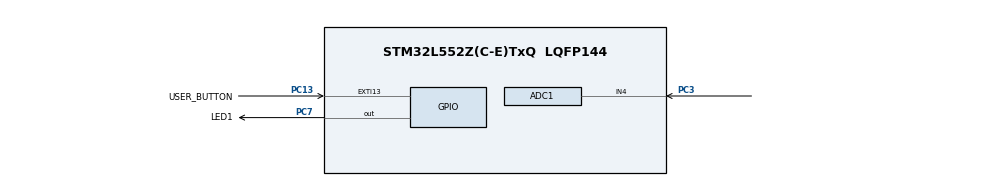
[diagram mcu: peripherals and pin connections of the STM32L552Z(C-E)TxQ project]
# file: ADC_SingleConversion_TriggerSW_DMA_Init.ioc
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ADC1.Channel-12\#ChannelRegularConversion=ADC_CHANNEL_4
ADC1.ClockPrescaler=ADC_CLOCK_SYNC_PCLK_DIV2
ADC1.EnableRegularConversion=ENABLE
ADC1.NbrOfConversionFlag=1
ADC1.OffsetNumber-12\#ChannelRegularConversion=ADC_OFFSET_NONE
ADC1.Rank-12\#ChannelRegularConversion=1
ADC1.SamplingTime-12\#ChannelRegularConversion=ADC_SAMPLETIME_47CYCLES_5
ADC1.master=1
Dma.ADC1.0.Channel_PRIV_NPRIV=DMA_CHANNEL_NPRIV_DISABLE
Dma.ADC1.0.Direction=DMA_PERIPH_TO_MEMORY
Dma.ADC1.0.EventEnable=DISABLE
Dma.ADC1.0.Instance=DMA1_Channel1
Dma.ADC1.0.MemDataAlignment=DMA_MDATAALIGN_HALFWORD
Dma.ADC1.0.MemInc=DMA_MINC_ENABLE
Dma.ADC1.0.Mode=DMA_NORMAL
Dma.ADC1.0.PeriphDataAlignment=DMA_PDATAALIGN_HALFWORD
Dma.ADC1.0.PeriphInc=DMA_PINC_DISABLE
Dma.ADC1.0.Polarity=HAL_DMAMUX_REQ_GEN_RISING
Dma.ADC1.0.Priority=DMA_PRIORITY_LOW
Dma.ADC1.0.RequestNumber=1
Dma.ADC1.0.SignalID=NONE
Dma.ADC1.0.SyncEnable=DISABLE
Dma.ADC1.0.SyncPolarity=HAL_DMAMUX_SYNC_NO_EVENT
Dma.ADC1.0.SyncRequestNumber=1
Dma.ADC1.0.SyncSignalID=NONE
Dma.Request0=ADC1
Mcu.Family=STM32L5
Mcu.Name=STM32L552Z(C-E)TxQ
Mcu.Package=LQFP144
NVIC.DMA1_Channel1_IRQn=true\:0\:0\:false\:false\:true\:false\:true\:true
NVIC.PriorityGroup=NVIC_PRIORITYGROUP_3
PC13.GPIO_Label=USER_BUTTON
PC13.Signal=GPXTI13
PC3.Signal=ADCx_IN4
PC7.GPIO_Label=LED1
PC7.Signal=GPIO_Output
ProjectManager.HeapSize=0x200
ProjectManager.StackSize=0x400
ProjectManager.TargetToolchain=EWARM V8.32
RCC.ADCCLockSelection=RCC_ADCCLKSOURCE_SYSCLK
RCC.ADCFreq_Value=110000000
RCC.AHBFreq_Value=110000000
RCC.APB1Freq_Value=110000000
RCC.APB1TimFreq_Value=110000000
RCC.APB2Freq_Value=110000000
RCC.APB2TimFreq_Value=110000000
RCC.CortexFreq_Value=110000000
RCC.HCLKFreq_Value=110000000
RCC.HSE_VALUE=16000000
RCC.HSI48_VALUE=48000000
RCC.HSI_VALUE=16000000
RCC.LSE_VALUE=32768
RCC.MSI_VALUE=4000000
RCC.PLLN=55
RCC.PLLSAI1N=24
RCC.RTCClockSelection=RCC_RTCCLKSOURCE_LSE
RCC.SYSCLKFreq_VALUE=110000000
RCC.SYSCLKSource=RCC_SYSCLKSOURCE_PLLCLK
RCC.USBFreq_Value=48000000
RCC.VCOOutputFreq_Value=220000000
SH.ADCx_IN4.0=ADC1_IN4,IN4-Single-Ended
VP_ICACHE_VS_ICACHE.Mode=DirectMappedCache
VP_PWR_VS_DBSignals.Mode=DisableDeadBatterySignals
board=custom

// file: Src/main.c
/* USER CODE BEGIN Header */
/**
  ******************************************************************************
  * @file    Examples_LL/ADC/ADC_SingleConversion_TriggerSW_DMA_Init/Src/main.c
  * @author  MCD Application Team
  * @brief   This example describes how to use a ADC peripheral to perform
  *          a single ADC conversion of a channel, at each software start.
  *          Example using programming model: DMA transfer
  *          (for programming models polling or interrupt, refer to
  *          other examples).
  *          This example is based on the STM32L5xx ADC LL API;
  *          Peripheral initialization done using LL unitary services functions.
  ******************************************************************************
  * @attention
  *
  * Copyright (c) 2019 STMicroelectronics.
  * All rights reserved.
  *
  * This software is licensed under terms that can be found in the LICENSE file
  * in the root directory of this software component.
  * If no LICENSE file comes with this software, it is provided AS-IS.
  *
  ******************************************************************************
  */
/* USER CODE END Header */
#include "main.h"

/* USER CODE BEGIN PD */

/* Definitions of ADC hardware constraints delays */
/* Note: Only ADC IP HW delays are defined in ADC LL driver driver,           */
/*       not timeout values:                                                  */
/*       Timeout values for ADC operations are dependent to device clock      */
/*       configuration (system clock versus ADC clock),                       */
/*       and therefore must be defined in user application.                   */
/*       Refer to @ref ADC_LL_EC_HW_DELAYS for description of ADC timeout     */
/*       values definition.                                                   */

  /* Timeout values for ADC operations. */
  /* (calibration, enable settling time, disable settling time, ...)          */
  /* Values defined to be higher than worst cases: low clock frequency,       */
  /* maximum prescalers.                                                      */
  #define ADC_CALIBRATION_TIMEOUT_MS       (   1U)
  #define ADC_ENABLE_TIMEOUT_MS            (   1U)
  #define ADC_DISABLE_TIMEOUT_MS           (   1U)
  #define ADC_STOP_CONVERSION_TIMEOUT_MS   (   1U)
  #define ADC_CONVERSION_TIMEOUT_MS        ( 500U)

  /* Delay between ADC end of calibration and ADC enable.                     */
  /* Delay estimation in CPU cycles: Case of ADC enable done                  */
  /* immediately after ADC calibration, ADC clock setting slow                */
  /* (LL_ADC_CLOCK_ASYNC_DIV32). Use a higher delay if ratio                  */
  /* (CPU clock / ADC clock) is above 32.                                     */
  #define ADC_DELAY_CALIB_ENABLE_CPU_CYCLES  (LL_ADC_DELAY_CALIB_ENABLE_ADC_CYCLES * 32)

/* Definitions of environment analog values */
  /* Value of analog reference voltage (Vref+), connected to analog voltage   */
  /* supply Vdda (unit: mV).                                                  */
  #define VDDA_APPLI                       (3300UL)

/* Definitions of data related to this example */
  /* Definition of ADCx conversions data table size */
  #define ADC_CONVERTED_DATA_BUFFER_SIZE   (   4UL)

  /* Init variable out of expected ADC conversion data range */
  #define VAR_CONVERTED_DATA_INIT_VALUE    (__LL_ADC_DIGITAL_SCALE(LL_ADC_RESOLUTION_12B) + 1)

/* USER CODE END PD */

/* USER CODE BEGIN PV */

/* Variables for ADC conversion data */
__IO uint16_t aADCxConvertedData[ADC_CONVERTED_DATA_BUFFER_SIZE]; /* ADC group regular conversion data */

/* Variables for ADC conversion data computation to physical values */
__IO uint16_t aADCxConvertedData_Voltage_mVolt[ADC_CONVERTED_DATA_BUFFER_SIZE];  /* Value of voltage calculated from ADC conversion data (unit: mV) (array of data) */

/* Variable to report status of DMA transfer of ADC group regular conversions */
/*  0: DMA transfer is not completed                                          */
/*  1: DMA transfer is completed                                              */
/*  2: DMA transfer has not yet been started yet (initial state)              */
__IO uint8_t ubDmaTransferStatus = 2U; /* Variable set into DMA interruption callback */

/* USER CODE END PV */

void SystemClock_Config(void);
static void MX_GPIO_Init(void);
static void MX_DMA_Init(void);
static void MX_ICACHE_Init(void);
static void MX_ADC1_Init(void);
/* USER CODE BEGIN PFP */

void     Activate_ADC(void);
void     LED_On(void);
void     LED_Off(void);
void     LED_Blinking(uint32_t Period);
void     UserButton_Init(void);

/* USER CODE END PFP */

int main(void)
{
  /* USER CODE BEGIN 1 */

  uint32_t tmp_index_adc_converted_data = 0UL;

  /* USER CODE END 1 */

  /* MCU Configuration--------------------------------------------------------*/

  /* Reset of all peripherals, Initializes the Flash interface and the Systick. */
  LL_APB2_GRP1_EnableClock(LL_APB2_GRP1_PERIPH_SYSCFG);
  LL_APB1_GRP1_EnableClock(LL_APB1_GRP1_PERIPH_PWR);

  /* System interrupt init*/
  NVIC_SetPriorityGrouping(NVIC_PRIORITYGROUP_3);

  /** Disable the internal Pull-Up in Dead Battery pins of UCPD peripheral
  */
  LL_PWR_DisableUCPDDeadBattery();

  /* Configure the system clock */
  SystemClock_Config();

  /* USER CODE BEGIN SysInit */

  /* Init variable containing ADC conversion data */
  for (tmp_index_adc_converted_data = 0; tmp_index_adc_converted_data < ADC_CONVERTED_DATA_BUFFER_SIZE; tmp_index_adc_converted_data++)
  {
    aADCxConvertedData[tmp_index_adc_converted_data] = VAR_CONVERTED_DATA_INIT_VALUE;
  }

  /* USER CODE END SysInit */

  /* Initialize all configured peripherals */
  MX_GPIO_Init();
  MX_DMA_Init();
  MX_ICACHE_Init();
  MX_ADC1_Init();
  /* USER CODE BEGIN 2 */

  /* Initialize button in EXTI mode */
  UserButton_Init();

  /* Activate ADC */
  /* Perform ADC activation procedure to make it ready to convert. */
  Activate_ADC();

  /* USER CODE END 2 */

  /* Infinite loop */
  /* USER CODE BEGIN WHILE */
  while (1)
  {
    /* Note: ADC group regular conversion start is done into push button      */
    /*       IRQ handler, refer to function "UserButton_Callback()".          */

    /* Note: LED state depending on DMA transfer status is set into DMA       */
    /*       IRQ handler,                                                     */
    /*       refer to functions "AdcDmaTransferComplete_Callback()"           */
    /*       and "AdcDmaTransferHalf_Callback()".                             */

    /* Note: ADC conversions data are stored into array                       */
    /*       "aADCxConvertedData"                                             */
    /*       (for debug: see variable content into watch window).             */

    /* Note: ADC conversion data are computed to physical values              */
    /*       into array "aADCxConvertedData_Voltage_mVolt"                    */
    /*       using ADC LL driver helper macro "__LL_ADC_CALC_DATA_TO_VOLTAGE()". */
    /*       (for debug: see variable content into watch window).             */

    /* USER CODE END WHILE */

  }
}

void SystemClock_Config(void)
{
  LL_FLASH_SetLatency(LL_FLASH_LATENCY_5);
  while(LL_FLASH_GetLatency()!= LL_FLASH_LATENCY_5)
  {
  }

  LL_PWR_SetRegulVoltageScaling(LL_PWR_REGU_VOLTAGE_SCALE0);
  LL_RCC_MSI_Enable();

   /* Wait till MSI is ready */
  while(LL_RCC_MSI_IsReady() != 1)
  {
  }

  LL_RCC_MSI_EnableRangeSelection();
  LL_RCC_MSI_SetRange(LL_RCC_MSIRANGE_6);
  LL_RCC_MSI_SetCalibTrimming(0);
  LL_RCC_PLL_ConfigDomain_SYS(LL_RCC_PLLSOURCE_MSI, LL_RCC_PLLM_DIV_1, 55, LL_RCC_PLLR_DIV_2);
  LL_RCC_PLL_EnableDomain_SYS();
  LL_RCC_PLL_Enable();

   /* Wait till PLL is ready */
  while(LL_RCC_PLL_IsReady() != 1)
  {
  }

   /* Intermediate AHB prescaler 2 when target frequency clock is higher than 80 MHz */
   LL_RCC_SetAHBPrescaler(LL_RCC_SYSCLK_DIV_2);

  LL_RCC_SetSysClkSource(LL_RCC_SYS_CLKSOURCE_PLL);

   /* Wait till System clock is ready */
  while(LL_RCC_GetSysClkSource() != LL_RCC_SYS_CLKSOURCE_STATUS_PLL)
  {
  }

  /* Insure 1us transition state at intermediate medium speed clock*/
  for (__IO uint32_t i = (RCC_MAX_FREQUENCY_MHZ >> 1); i !=0; i--);

  LL_RCC_SetAHBPrescaler(LL_RCC_SYSCLK_DIV_1);
  LL_RCC_SetAPB1Prescaler(LL_RCC_APB1_DIV_1);
  LL_RCC_SetAPB2Prescaler(LL_RCC_APB2_DIV_1);

  LL_Init1msTick(110000000);

  LL_SetSystemCoreClock(110000000);
}

static void MX_ADC1_Init(void)
{

  LL_ADC_InitTypeDef ADC_InitStruct = {0};
  LL_ADC_REG_InitTypeDef ADC_REG_InitStruct = {0};
  LL_ADC_CommonInitTypeDef ADC_CommonInitStruct = {0};

  LL_GPIO_InitTypeDef GPIO_InitStruct = {0};

  LL_RCC_SetADCClockSource(LL_RCC_ADC_CLKSOURCE_SYSCLK);

  /* Peripheral clock enable */
  LL_AHB2_GRP1_EnableClock(LL_AHB2_GRP1_PERIPH_ADC);

  LL_AHB2_GRP1_EnableClock(LL_AHB2_GRP1_PERIPH_GPIOC);
  /**ADC1 GPIO Configuration
  PC3   ------> ADC1_IN4
  */
  GPIO_InitStruct.Pin = LL_GPIO_PIN_3;
  GPIO_InitStruct.Mode = LL_GPIO_MODE_ANALOG;
  GPIO_InitStruct.Pull = LL_GPIO_PULL_NO;
  LL_GPIO_Init(GPIOC, &GPIO_InitStruct);

  /* ADC1 DMA Init */

  /* ADC1 Init */
  LL_DMA_SetPeriphRequest(DMA1, LL_DMA_CHANNEL_1, LL_DMAMUX_REQ_ADC1);

  LL_DMA_SetDataTransferDirection(DMA1, LL_DMA_CHANNEL_1, LL_DMA_DIRECTION_PERIPH_TO_MEMORY);

  LL_DMA_SetChannelPriorityLevel(DMA1, LL_DMA_CHANNEL_1, LL_DMA_PRIORITY_LOW);

  LL_DMA_SetMode(DMA1, LL_DMA_CHANNEL_1, LL_DMA_MODE_NORMAL);

  LL_DMA_SetPeriphIncMode(DMA1, LL_DMA_CHANNEL_1, LL_DMA_PERIPH_NOINCREMENT);

  LL_DMA_SetMemoryIncMode(DMA1, LL_DMA_CHANNEL_1, LL_DMA_MEMORY_INCREMENT);

  LL_DMA_SetPeriphSize(DMA1, LL_DMA_CHANNEL_1, LL_DMA_PDATAALIGN_HALFWORD);

  LL_DMA_SetMemorySize(DMA1, LL_DMA_CHANNEL_1, LL_DMA_MDATAALIGN_HALFWORD);

  LL_DMA_DisableChannelPrivilege(DMA1, LL_DMA_CHANNEL_1);

  /* USER CODE BEGIN ADC1_Init 1 */

  /* Select ADC as DMA transfer request */
  LL_DMA_SetPeriphRequest(DMA1,
                          LL_DMA_CHANNEL_1,
                          LL_DMAMUX_REQ_ADC1);

  /* Set DMA transfer addresses of source and destination */
  LL_DMA_ConfigAddresses(DMA1,
                         LL_DMA_CHANNEL_1,
                         LL_ADC_DMA_GetRegAddr(ADC1, LL_ADC_DMA_REG_REGULAR_DATA),
                         (uint32_t)&aADCxConvertedData,
                         LL_DMA_DIRECTION_PERIPH_TO_MEMORY);

  /* Set DMA transfer size */
  LL_DMA_SetDataLength(DMA1,
                       LL_DMA_CHANNEL_1,
                       ADC_CONVERTED_DATA_BUFFER_SIZE);

  /* Enable DMA transfer interruption: transfer complete */
  LL_DMA_EnableIT_TC(DMA1,
                     LL_DMA_CHANNEL_1);

  /* Enable DMA transfer interruption: half transfer */
  LL_DMA_EnableIT_HT(DMA1,
                     LL_DMA_CHANNEL_1);

  /* Enable DMA transfer interruption: transfer error */
  LL_DMA_EnableIT_TE(DMA1,
                     LL_DMA_CHANNEL_1);

  /*## Activation of DMA #####################################################*/
  /* Enable the DMA transfer */
  LL_DMA_EnableChannel(DMA1,
                       LL_DMA_CHANNEL_1);
  /* Configure NVIC to enable ADC1 interruptions */
  NVIC_SetPriority(ADC1_2_IRQn, 0); /* ADC IRQ greater priority than DMA IRQ */
  NVIC_EnableIRQ(ADC1_2_IRQn);

  /* USER CODE END ADC1_Init 1 */

  /** Common config
  */
  ADC_InitStruct.Resolution = LL_ADC_RESOLUTION_12B;
  ADC_InitStruct.DataAlignment = LL_ADC_DATA_ALIGN_RIGHT;
  ADC_InitStruct.LowPowerMode = LL_ADC_LP_MODE_NONE;
  LL_ADC_Init(ADC1, &ADC_InitStruct);
  ADC_REG_InitStruct.TriggerSource = LL_ADC_REG_TRIG_SOFTWARE;
  ADC_REG_InitStruct.SequencerLength = LL_ADC_REG_SEQ_SCAN_DISABLE;
  ADC_REG_InitStruct.SequencerDiscont = LL_ADC_REG_SEQ_DISCONT_DISABLE;
  ADC_REG_InitStruct.ContinuousMode = LL_ADC_REG_CONV_SINGLE;
  ADC_REG_InitStruct.DMATransfer = LL_ADC_REG_DMA_TRANSFER_LIMITED;
  ADC_REG_InitStruct.Overrun = LL_ADC_REG_OVR_DATA_PRESERVED;
  LL_ADC_REG_Init(ADC1, &ADC_REG_InitStruct);
  LL_ADC_SetOverSamplingScope(ADC1, LL_ADC_OVS_DISABLE);
  ADC_CommonInitStruct.CommonClock = LL_ADC_CLOCK_SYNC_PCLK_DIV2;
  ADC_CommonInitStruct.Multimode = LL_ADC_MULTI_INDEPENDENT;
  LL_ADC_CommonInit(__LL_ADC_COMMON_INSTANCE(ADC1), &ADC_CommonInitStruct);

  /* Disable ADC deep power down (enabled by default after reset state) */
  LL_ADC_DisableDeepPowerDown(ADC1);
  /* Enable ADC internal voltage regulator */
  LL_ADC_EnableInternalRegulator(ADC1);
  /* Delay for ADC internal voltage regulator stabilization. */
  /* Compute number of CPU cycles to wait for, from delay in us. */
  /* Note: Variable divided by 2 to compensate partially */
  /* CPU processing cycles (depends on compilation optimization). */
  /* Note: If system core clock frequency is below 200kHz, wait time */
  /* is only a few CPU processing cycles. */
  uint32_t wait_loop_index;
  wait_loop_index = ((LL_ADC_DELAY_INTERNAL_REGUL_STAB_US * (SystemCoreClock / (100000 * 2))) / 10);
  while(wait_loop_index != 0)
  {
    wait_loop_index--;
  }

  /** Configure Regular Channel
  */
  LL_ADC_REG_SetSequencerRanks(ADC1, LL_ADC_REG_RANK_1, LL_ADC_CHANNEL_4);
  LL_ADC_SetChannelSamplingTime(ADC1, LL_ADC_CHANNEL_4, LL_ADC_SAMPLINGTIME_47CYCLES_5);
  LL_ADC_SetChannelSingleDiff(ADC1, LL_ADC_CHANNEL_4, LL_ADC_SINGLE_ENDED);
  /* USER CODE BEGIN ADC1_Init 2 */

  /* Configuration of ADC interruptions */
  /* Enable interruption ADC group regular overrun */
  LL_ADC_EnableIT_OVR(ADC1);

  /* USER CODE END ADC1_Init 2 */

}

static void MX_ICACHE_Init(void)
{

  /** Enable instruction cache in 1-way (direct mapped cache)
  */
  LL_ICACHE_SetMode(LL_ICACHE_1WAY);
  LL_ICACHE_Enable();

}

static void MX_DMA_Init(void)
{

  /* Init with LL driver */
  /* DMA controller clock enable */
  LL_AHB1_GRP1_EnableClock(LL_AHB1_GRP1_PERIPH_DMAMUX1);
  LL_AHB1_GRP1_EnableClock(LL_AHB1_GRP1_PERIPH_DMA1);

  /* DMA interrupt init */
  /* DMA1_Channel1_IRQn interrupt configuration */
  NVIC_SetPriority(DMA1_Channel1_IRQn, NVIC_EncodePriority(NVIC_GetPriorityGrouping(),0, 0));
  NVIC_EnableIRQ(DMA1_Channel1_IRQn);

}

static void MX_GPIO_Init(void)
{
  LL_EXTI_InitTypeDef EXTI_InitStruct = {0};
  LL_GPIO_InitTypeDef GPIO_InitStruct = {0};

  /* GPIO Ports Clock Enable */
  LL_AHB2_GRP1_EnableClock(LL_AHB2_GRP1_PERIPH_GPIOC);

  /**/
  LL_GPIO_ResetOutputPin(LED1_GPIO_Port, LED1_Pin);

  /**/
  LL_EXTI_SetEXTISource(LL_EXTI_EXTI_PORTC, LL_EXTI_EXTI_LINE13);

  /**/
  EXTI_InitStruct.Line_0_31 = LL_EXTI_LINE_13;
  EXTI_InitStruct.Line_32_63 = LL_EXTI_LINE_NONE;
  EXTI_InitStruct.LineCommand = ENABLE;
  EXTI_InitStruct.Mode = LL_EXTI_MODE_IT;
  EXTI_InitStruct.Trigger = LL_EXTI_TRIGGER_RISING;
  LL_EXTI_Init(&EXTI_InitStruct);

  /**/
  LL_GPIO_SetPinPull(USER_BUTTON_GPIO_Port, USER_BUTTON_Pin, LL_GPIO_PULL_NO);

  /**/
  LL_GPIO_SetPinMode(USER_BUTTON_GPIO_Port, USER_BUTTON_Pin, LL_GPIO_MODE_INPUT);

  /**/
  GPIO_InitStruct.Pin = LED1_Pin;
  GPIO_InitStruct.Mode = LL_GPIO_MODE_OUTPUT;
  GPIO_InitStruct.Speed = LL_GPIO_SPEED_FREQ_LOW;
  GPIO_InitStruct.OutputType = LL_GPIO_OUTPUT_PUSHPULL;
  GPIO_InitStruct.Pull = LL_GPIO_PULL_NO;
  LL_GPIO_Init(LED1_GPIO_Port, &GPIO_InitStruct);

}

/* USER CODE BEGIN 4 */
/**
  * @brief  Perform ADC activation procedure to make it ready to convert
  *         (ADC instance: ADC1).
  * @note   Operations:
  *         - ADC instance
  *           - Disable deep power down
  *           - Enable internal voltage regulator
  *           - Run ADC self calibration
  *           - Enable ADC
  *         - ADC group regular
  *           none: ADC conversion start-stop to be performed
  *                 after this function
  *         - ADC group injected
  *           none: ADC conversion start-stop to be performed
  *                 after this function
  * @param  None
  * @retval None
  */
void Activate_ADC(void)
{
  __IO uint32_t wait_loop_index = 0U;
  #if (USE_TIMEOUT == 1)
  uint32_t Timeout = 0U; /* Variable used for timeout management */
  #endif /* USE_TIMEOUT */

  /*## Operation on ADC hierarchical scope: ADC instance #####################*/

  /* Note: Hardware constraint (refer to description of the functions         */
  /*       below):                                                            */
  /*       On this STM32 series, setting of these features is conditioned to   */
  /*       ADC state:                                                         */
  /*       ADC must be disabled.                                              */
  /* Note: In this example, all these checks are not necessary but are        */
  /*       implemented anyway to show the best practice usages                */
  /*       corresponding to reference manual procedure.                       */
  /*       Software can be optimized by removing some of these checks, if     */
  /*       they are not relevant considering previous settings and actions    */
  /*       in user application.                                               */
  if (LL_ADC_IsEnabled(ADC1) == 0)
  {
    /* Disable ADC deep power down (enabled by default after reset state) */
    LL_ADC_DisableDeepPowerDown(ADC1);

    /* Enable ADC internal voltage regulator */
    LL_ADC_EnableInternalRegulator(ADC1);

    /* Delay for ADC internal voltage regulator stabilization.                */
    /* Compute number of CPU cycles to wait for, from delay in us.            */
    /* Note: Variable divided by 2 to compensate partially                    */
    /*       CPU processing cycles (depends on compilation optimization).     */
    /* Note: If system core clock frequency is below 200kHz, wait time        */
    /*       is only a few CPU processing cycles.                             */
    wait_loop_index = ((LL_ADC_DELAY_INTERNAL_REGUL_STAB_US * (SystemCoreClock / (100000 * 2))) / 10);
    while(wait_loop_index != 0)
    {
      wait_loop_index--;
    }

    /* Run ADC self calibration */
    LL_ADC_StartCalibration(ADC1, LL_ADC_SINGLE_ENDED);

    /* Poll for ADC effectively calibrated */
    #if (USE_TIMEOUT == 1)
    Timeout = ADC_CALIBRATION_TIMEOUT_MS;
    #endif /* USE_TIMEOUT */

    while (LL_ADC_IsCalibrationOnGoing(ADC1) != 0)
    {
    #if (USE_TIMEOUT == 1)
      /* Check Systick counter flag to decrement the time-out value */
      if (LL_SYSTICK_IsActiveCounterFlag())
      {
        if(Timeout-- == 0)
        {
        /* Time-out occurred. Set LED to blinking mode */
        LED_Blinking(LED_BLINK_ERROR);
        }
      }
    #endif /* USE_TIMEOUT */
    }

    /* Delay between ADC end of calibration and ADC enable.                   */
    /* Note: Variable divided by 2 to compensate partially                    */
    /*       CPU processing cycles (depends on compilation optimization).     */
    wait_loop_index = (ADC_DELAY_CALIB_ENABLE_CPU_CYCLES >> 1);
    while(wait_loop_index != 0)
    {
      wait_loop_index--;
    }

    /* Enable ADC */
    LL_ADC_Enable(ADC1);

    /* Poll for ADC ready to convert */
    #if (USE_TIMEOUT == 1)
    Timeout = ADC_ENABLE_TIMEOUT_MS;
    #endif /* USE_TIMEOUT */

    while (LL_ADC_IsActiveFlag_ADRDY(ADC1) == 0)
    {
    #if (USE_TIMEOUT == 1)
      /* Check Systick counter flag to decrement the time-out value */
      if (LL_SYSTICK_IsActiveCounterFlag())
      {
        if(Timeout-- == 0)
        {
        /* Time-out occurred. Set LED to blinking mode */
        LED_Blinking(LED_BLINK_ERROR);
        }
      }
    #endif /* USE_TIMEOUT */
    }

    /* Note: ADC flag ADRDY is not cleared here to be able to check ADC       */
    /*       status afterwards.                                               */
    /*       This flag should be cleared at ADC Deactivation, before a new    */
    /*       ADC activation, using function "LL_ADC_ClearFlag_ADRDY()".       */
  }

  /*## Operation on ADC hierarchical scope: ADC group regular ################*/
  /* Note: No operation on ADC group regular performed here.                  */
  /*       ADC group regular conversions to be performed after this function  */
  /*       using function:                                                    */
  /*       "LL_ADC_REG_StartConversion();"                                    */

  /*## Operation on ADC hierarchical scope: ADC group injected ###############*/
  /* Note: No operation on ADC group injected performed here.                 */
  /*       ADC group injected conversions to be performed after this function */
  /*       using function:                                                    */
  /*       "LL_ADC_INJ_StartConversion();"                                    */

}

/**
  * @brief  Turn-on LED1.
  * @param  None
  * @retval None
  */
void LED_On(void)
{
  /* Turn LED1 on */
  LL_GPIO_SetOutputPin(LED1_GPIO_Port, LED1_Pin);
}

/**
  * @brief  Turn-off LED1.
  * @param  None
  * @retval None
  */
void LED_Off(void)
{
  /* Turn LED1 off */
  LL_GPIO_ResetOutputPin(LED1_GPIO_Port, LED1_Pin);
}

/**
  * @brief  Set LED1 to Blinking mode for an infinite loop (toggle period based on value provided as input parameter).
  * @param  Period : Period of time (in ms) between each toggling of LED
  *   This parameter can be user defined values. Pre-defined values used in that example are :
  *     @arg LED_BLINK_FAST : Fast Blinking
  *     @arg LED_BLINK_SLOW : Slow Blinking
  *     @arg LED_BLINK_ERROR : Error specific Blinking
  * @retval None
  */
void LED_Blinking(uint32_t Period)
{
  /* Turn LED1 on */
  LL_GPIO_SetOutputPin(LED1_GPIO_Port, LED1_Pin);

  /* Toggle IO in an infinite loop */
  while (1)
  {
    LL_GPIO_TogglePin(LED1_GPIO_Port, LED1_Pin);
    LL_mDelay(Period);
  }
}

/**
  * @brief  Configures User push-button in EXTI Line Mode.
  * @param  None
  * @retval None
  */
void UserButton_Init(void)
{
  /* Enable the BUTTON Clock */
  USER_BUTTON_GPIO_CLK_ENABLE();

  /* Configure GPIO for BUTTON */
  LL_GPIO_SetPinMode(USER_BUTTON_GPIO_PORT, USER_BUTTON_PIN, LL_GPIO_MODE_INPUT);
  LL_GPIO_SetPinPull(USER_BUTTON_GPIO_PORT, USER_BUTTON_PIN, LL_GPIO_PULL_DOWN);

  /* if(Button_Mode == BUTTON_MODE_EXTI) */
  {
    /* Connect External Line to the GPIO */
    USER_BUTTON_SYSCFG_SET_EXTI();

    /* Enable a rising trigger EXTI line 13 Interrupt */
    USER_BUTTON_EXTI_LINE_ENABLE();
    USER_BUTTON_EXTI_FALLING_TRIG_ENABLE();

    /* Configure NVIC for USER_BUTTON_EXTI_IRQn */
    NVIC_EnableIRQ(USER_BUTTON_EXTI_IRQn);
    NVIC_SetPriority(USER_BUTTON_EXTI_IRQn,0x03);
  }
}

/******************************************************************************/
/*   USER IRQ HANDLER TREATMENT                                               */
/******************************************************************************/

/**
  * @brief  Function to manage IRQ Handler
  * @param  None
  * @retval None
  */
void UserButton_Callback(void)
{

  /* Update status variable of DMA transfer before performing the first       */
  /* ADC conversion start.                                                    */
  if (ubDmaTransferStatus == 2)
  {
    /* Update status variable of DMA transfer */
    ubDmaTransferStatus = 0;
  }

  /* Start ADC group regular conversion */
  /* Note: Hardware constraint (refer to description of the function          */
  /*       below):                                                            */
  /*       On this STM32 series, setting of this feature is conditioned to     */
  /*       ADC state:                                                         */
  /*       ADC must be enabled without conversion on going on group regular,  */
  /*       without ADC disable command on going.                              */
  /* Note: In this example, all these checks are not necessary but are        */
  /*       implemented anyway to show the best practice usages                */
  /*       corresponding to reference manual procedure.                       */
  /*       Software can be optimized by removing some of these checks, if     */
  /*       they are not relevant considering previous settings and actions    */
  /*       in user application.                                               */
  if ((LL_ADC_IsEnabled(ADC1) == 1)               &&
      (LL_ADC_IsDisableOngoing(ADC1) == 0)        &&
      (LL_ADC_REG_IsConversionOngoing(ADC1) == 0)   )
  {
    LL_ADC_REG_StartConversion(ADC1);
  }
  else
  {
    /* Error: ADC conversion start could not be performed */
    LED_Blinking(LED_BLINK_ERROR);
  }
}

/**
  * @brief  DMA transfer complete callback
  * @note   This function is executed when the transfer complete interrupt
  *         is generated
  * @retval None
  */
void AdcDmaTransferComplete_Callback()
{
  uint32_t tmp_index = 0;

  /* Computation of ADC conversions raw data to physical values               */
  /* using LL ADC driver helper macro.                                        */
  /* Management of the 2nd half of the buffer */
  for (tmp_index = (ADC_CONVERTED_DATA_BUFFER_SIZE/2); tmp_index < ADC_CONVERTED_DATA_BUFFER_SIZE; tmp_index++)
  {
    aADCxConvertedData_Voltage_mVolt[tmp_index] = __LL_ADC_CALC_DATA_TO_VOLTAGE(VDDA_APPLI, aADCxConvertedData[tmp_index], LL_ADC_RESOLUTION_12B);
  }

  /* Update status variable of DMA transfer */
  ubDmaTransferStatus = 1;

  /* Set LED depending on DMA transfer status */
  /* - Turn-on if DMA transfer is completed */
  /* - Turn-off if DMA transfer is not completed */
  LED_On();

}

/**
  * @brief  DMA half transfer callback
  * @note   This function is executed when the half transfer interrupt
  *         is generated
  * @retval None
  */
void AdcDmaTransferHalf_Callback()
{
  uint32_t tmp_index = 0;

  /* Computation of ADC conversions raw data to physical values               */
  /* using LL ADC driver helper macro.                                        */
  /* Management of the 1st half of the buffer */
  for (tmp_index = 0; tmp_index < (ADC_CONVERTED_DATA_BUFFER_SIZE/2); tmp_index++)
  {
    aADCxConvertedData_Voltage_mVolt[tmp_index] = __LL_ADC_CALC_DATA_TO_VOLTAGE(VDDA_APPLI, aADCxConvertedData[tmp_index], LL_ADC_RESOLUTION_12B);
  }

  /* Update status variable of DMA transfer */
  ubDmaTransferStatus = 0;

  /* Set LED depending on DMA transfer status */
  /* - Turn-on if DMA transfer is completed */
  /* - Turn-off if DMA transfer is not completed */
  LED_Off();

}

/**
  * @brief  DMA transfer error callback
  * @note   This function is executed when the transfer error interrupt
  *         is generated during DMA transfer
  * @retval None
  */
void AdcDmaTransferError_Callback()
{
  /* Error detected during DMA transfer */
  LED_Blinking(LED_BLINK_ERROR);
}

/**
  * @brief  ADC group regular overrun interruption callback
  * @note   This function is executed when ADC group regular
  *         overrun error occurs.
  * @retval None
  */
void AdcGrpRegularOverrunError_Callback(void)
{
  /* Note: Disable ADC interruption that caused this error before entering in */
  /*       infinite loop below.                                               */

  /* Disable ADC group regular overrun interruption */
  LL_ADC_DisableIT_OVR(ADC1);

  /* Error from ADC */
  LED_Blinking(LED_BLINK_ERROR);
}

/* USER CODE END 4 */

void Error_Handler(void)
{
  while(1)
  {
  }
}
